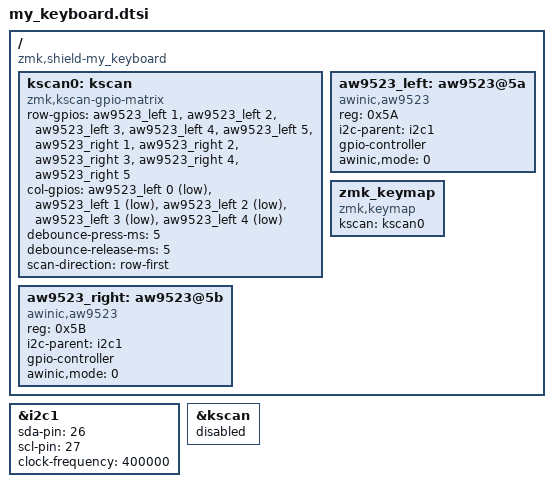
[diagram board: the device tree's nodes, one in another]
#include <dt-bindings/zmk/matrix_transform.h>
#include <dt-bindings/gpio/gpio.h>

/ {
    compatible = "zmk,shield-my_keyboard", "zmk,shield";

    kscan0: kscan {
        compatible = "zmk,kscan-gpio-matrix";
        // 行：左AW9523(P1-P5) + 右AW9523(P1-P5)
        row-gpios = <&aw9523_left 1 GPIO_ACTIVE_HIGH>,
                    <&aw9523_left 2 GPIO_ACTIVE_HIGH>,
                    <&aw9523_left 3 GPIO_ACTIVE_HIGH>,
                    <&aw9523_left 4 GPIO_ACTIVE_HIGH>,
                    <&aw9523_left 5 GPIO_ACTIVE_HIGH>,
                    <&aw9523_right 1 GPIO_ACTIVE_HIGH>,
                    <&aw9523_right 2 GPIO_ACTIVE_HIGH>,
                    <&aw9523_right 3 GPIO_ACTIVE_HIGH>,
                    <&aw9523_right 4 GPIO_ACTIVE_HIGH>,
                    <&aw9523_right 5 GPIO_ACTIVE_HIGH>;
        // 列：P0-P4（对应你说的P0-P5），按下低电平
        col-gpios = <&aw9523_left 0 GPIO_ACTIVE_LOW>,
                    <&aw9523_left 1 GPIO_ACTIVE_LOW>,
                    <&aw9523_left 2 GPIO_ACTIVE_LOW>,
                    <&aw9523_left 3 GPIO_ACTIVE_LOW>,
                    <&aw9523_left 4 GPIO_ACTIVE_LOW>;
        debounce-press-ms = <5>;
        debounce-release-ms = <5>;
        scan-direction = "row-first";
    };

    // 左AW9523（地址0x5A）
    aw9523_left: aw9523@5a {
        compatible = "awinic,aw9523";
        reg = <0x5A>;
        i2c-parent = <&i2c1>;
        gpio-controller;
        #gpio-cells = <2>;
        awinic,mode = <0>; // GPIO模式
    };

    // 右AW9523（地址0x5B）
    aw9523_right: aw9523@5b {
        compatible = "awinic,aw9523";
        reg = <0x5B>;
        i2c-parent = <&i2c1>;
        gpio-controller;
        #gpio-cells = <2>;
        awinic,mode = <0>;
    };

    zmk_keymap {
        compatible = "zmk,keymap";
        kscan = <&kscan0>;
    };
};

// 启用Nice!Nano I2C1总线
&i2c1 {
    status = "okay";
    sda-pin = <26>;
    scl-pin = <27>;
    clock-frequency = <400000>;
};

// 禁用默认矩阵扫描
&kscan {
    status = "disabled";
};
